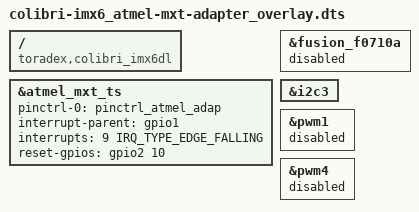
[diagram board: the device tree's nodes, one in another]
// SPDX-License-Identifier: GPL-2.0-or-later OR MIT
/*
 * Copyright 2020-2021 Toradex
 */

// Atmel MXT touchscreen for the 7inch and 10inch display orderable at Toradex. Compatible with a Capacitive Touch Adapter.

/dts-v1/;
/plugin/;

#include <dt-bindings/gpio/gpio.h>
#include <dt-bindings/interrupt-controller/irq.h>

/ {
	compatible = "toradex,colibri_imx6dl";
};

&atmel_mxt_ts {
	pinctrl-0 = <&pinctrl_atmel_adap>;
	interrupt-parent = <&gpio1>;
	interrupts = <9 IRQ_TYPE_EDGE_FALLING>;
	reset-gpios = <&gpio2 10 GPIO_ACTIVE_HIGH>;
	status = "okay";
};

&fusion_f0710a {
	status = "disabled";
};

&i2c3 {
	status = "okay";
};

&pwm1 {
	status = "disabled";
};

&pwm4{
	status = "disabled";
};
